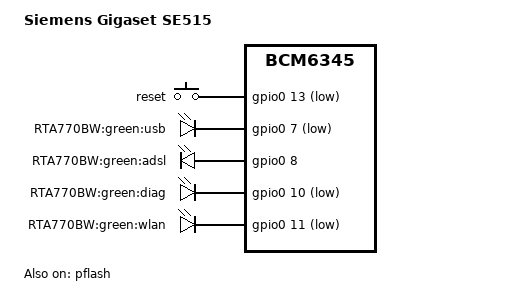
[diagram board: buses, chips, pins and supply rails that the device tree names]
/dts-v1/;

#include "bcm6345.dtsi"

#include <dt-bindings/input/input.h>

/ {
	model = "Siemens Gigaset SE515";
	compatible = "dynalink,rta770bw", "brcm,bcm6345";

	chosen {
		bootargs = "root=/dev/mtdblock2 rootfstype=squashfs,jffs2 noinitrd console=ttyS0,115200";
	};

	gpio-keys-polled {
		compatible = "gpio-keys-polled";
		#address-cells = <1>;
		#size-cells = <0>;
		poll-interval = <20>;
		debounce-interval = <60>;

		reset {
			label = "reset";
			gpios = <&gpio0 13 1>;
			linux,code = <KEY_RESTART>;
		};
        };

	gpio-leds {
		compatible = "gpio-leds";

		usb {
			label = "RTA770BW:green:usb";
			gpios = <&gpio0 7 1>;
		};

		adsl {
			label = "RTA770BW:green:adsl";
			gpios = <&gpio0 8 0>;
		};

		diag {
			label = "RTA770BW:green:diag";
			gpios = <&gpio0 10 1>;
		};

		wlan {
			label = "RTA770BW:green:wlan";
			gpios = <&gpio0 11 1>;
		};
	};
};

&pflash {
	status = "ok";

	linux,part-probe = "bcm63xxpart";

	cfe@0 {
		label = "CFE";
		reg = <0x000000 0x010000>;
		read-only;
	};

	linux@10000 {
		label = "linux";
		reg = <0x010000 0x3e0000>;
	};

	nvram@3f0000 {
		label = "nvram";
		reg = <0x3f0000 0x010000>;
	};
};
